# ATmega1284RFR2 device description
Architecture: AVR8; Family: megaAVR
Registers are 8-bit, access not given, no defined reset value unless marked. A register's access mark holds for its fields unless they carry their own. Offsets are from the block's base; [hi:lo] are bit positions; 'fields as' and 'values as' point back to an identical list.

## TC2 (TC8_ASYNC module) — Timer/Counter, 8-bit Async
Instances: TC2 0x00
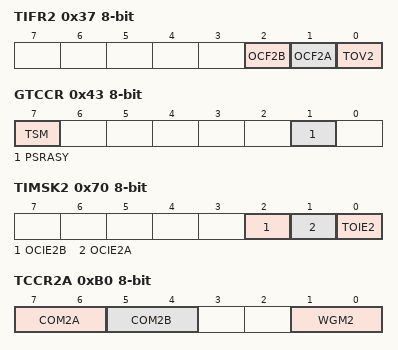
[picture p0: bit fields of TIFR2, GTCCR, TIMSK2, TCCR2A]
0x37 TIFR2 — Timer/Counter Interrupt Flag Register
  [2] OCF2B — Output Compare Flag 2 B
  [1] OCF2A — Output Compare Flag 2 A
  [0] TOV2 — Timer/Counter2 Overflow Flag
0x43 GTCCR — General Timer Counter Control register
  [7] TSM — Timer/Counter Synchronization Mode
  [1] PSRASY — Prescaler Reset Timer/Counter2
0x70 TIMSK2 — Timer/Counter Interrupt Mask register
  [2] OCIE2B — Timer/Counter2 Output Compare Match B Interrupt Enable
  [1] OCIE2A — Timer/Counter2 Output Compare Match A Interrupt Enable
  [0] TOIE2 — Timer/Counter2 Overflow Interrupt Enable
0xB0 TCCR2A — Timer/Counter2 Control Register A
  [7:6] COM2A — Compare Match Output A Mode
    0=Normal port operation, OC2A disconnected; 1=Toggle OC2A on Compare Match; 2=Clear OC2A on Compare Match; 3=Set OC2A on Compare Match
  [5:4] COM2B — Compare Match Output B Mode
    0=Normal port operation, OC2B disconnected; 1=Toggle OC2B on Compare Match; 2=Clear OC2B on Compare Match; 3=Set OC2B on Compare Match
  [1:0] WGM2 — Waveform Generation Mode
    0=Normal mode of operation; 1=PWM, phase correct, TOP=0xFF; 2=CTC, TOP = OCRA; 3=Fast PWM, TOP=0xFF; 5=PWM, Phase correct, TOP = OCRA; 7=Fast PWM, TOP=OCRA
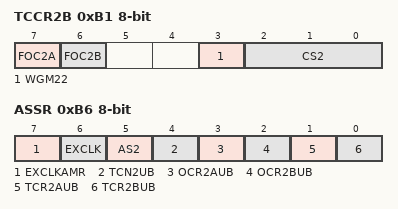
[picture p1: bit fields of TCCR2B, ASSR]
0xB1 TCCR2B — Timer/Counter2 Control Register B
  [7] FOC2A — Force Output Compare A
  [6] FOC2B — Force Output Compare B
  [3] WGM22 — Waveform Generation Mode
  [2:0] CS2 — Clock Select
    0=No clock source (Timer/Counter2 stopped); 1=clk_T2S/1 (no prescaling); 2=clk_T2S/8 (from prescaler); 3=clk_T2S/32 (from prescaler); 4=clk_T2S/64 (from prescaler); 5=clk_T2S/128 (from prescaler); 6=clk_T2S/256 (from prescaler); 7=clk_T2S/1024 (from prescaler)
0xB2 TCNT2 — Timer/Counter2
0xB3 OCR2A — Timer/Counter2 Output Compare Register A
0xB4 OCR2B — Timer/Counter2 Output Compare Register B
0xB6 ASSR — Asynchronous Status Register
  [7] EXCLKAMR — Enable External Clock Input for AMR
  [6] EXCLK — Enable External Clock Input
  [5] AS2 — Timer/Counter2 Asynchronous Mode
  [4] TCN2UB — Timer/Counter2 Update Busy
  [3] OCR2AUB — Timer/Counter2 Output Compare Register A Update Busy
  [2] OCR2BUB — Timer/Counter2 Output Compare Register B Update Busy
  [1] TCR2AUB — Timer/Counter2 Control Register A Update Busy
  [0] TCR2BUB — Timer/Counter2 Control Register B Update Busy

## WDT — Watchdog Timer
Instances: WDT 0x00
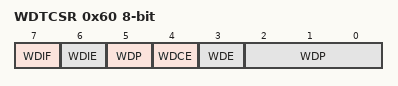
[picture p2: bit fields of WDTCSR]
0x60 WDTCSR — Watchdog Timer Control Register
  [7] WDIF — Watchdog Timeout Interrupt Flag
  [6] WDIE — Watchdog Timeout Interrupt Enable
  [4] WDCE — Watchdog Change Enable
  [3] WDE — Watch Dog Enable
  [5,2:0] WDP — Watchdog Timer Prescaler Bits
    0=Oscillator Cycles 2K; 1=Oscillator Cycles 4K; 2=Oscillator Cycles 8K; 3=Oscillator Cycles 16K; 4=Oscillator Cycles 32K; 5=Oscillator Cycles 64K; 6=Oscillator Cycles 128K; 7=Oscillator Cycles 256K; 8=Oscillator Cycles 512K; 9=Oscillator Cycles 1024K

## TC5 (TC16 module) — Timer/Counter, 16-bit
Instances: TC5 0x00
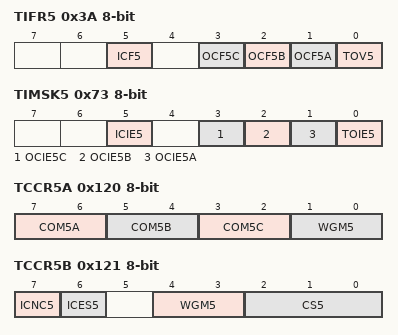
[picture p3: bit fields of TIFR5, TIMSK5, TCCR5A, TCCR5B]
0x3A TIFR5 — Timer/Counter5 Interrupt Flag Register
  [5] ICF5 — Timer/Counter5 Input Capture Flag
  [3] OCF5C — Timer/Counter5 Output Compare C Match Flag
  [2] OCF5B — Timer/Counter5 Output Compare B Match Flag
  [1] OCF5A — Timer/Counter5 Output Compare A Match Flag
  [0] TOV5 — Timer/Counter5 Overflow Flag
0x73 TIMSK5 — Timer/Counter5 Interrupt Mask Register
  [5] ICIE5 — Timer/Counter5 Input Capture Interrupt Enable
  [3] OCIE5C — Timer/Counter5 Output Compare C Match Interrupt Enable
  [2] OCIE5B — Timer/Counter5 Output Compare B Match Interrupt Enable
  [1] OCIE5A — Timer/Counter5 Output Compare A Match Interrupt Enable
  [0] TOIE5 — Timer/Counter5 Overflow Interrupt Enable
0x120 TCCR5A — Timer/Counter5 Control Register A
  [7:6] COM5A — Compare Output Mode for Channel A
    0=Normal operation
  [5:4] COM5B — Compare Output Mode for Channel B
    0=Normal operation
  [3:2] COM5C — Compare Output Mode for Channel C
    0=Normal operation
  [1:0] WGM5 — Waveform Generation Mode
    0=Normal mode of operation; 1=PWM, phase correct, 8-bit; 2=PWM, phase correct, 9-bit; 3=PWM, phase correct, 10-bit; 4=CTC, TOP = OCRnA; 5=Fast PWM, 8-bit; 6=Fast PWM, 9-bit; 7=Fast PWM, 10-bit; 8=PWM, Phase and frequency correct, TOP = ICRn; 9=PWM, Phase and frequency correct, TOP = OCRnA; 10=PWM, Phase correct, TOP = ICRn; 11=PWM, Phase correct, TOP = OCRnA; 12=CTC, TOP = OCRnA; 14=Fast PWM, TOP = ICRn; 15=Fast PWM, TOP = OCRnA
0x121 TCCR5B — Timer/Counter5 Control Register B
  [7] ICNC5 — Input Capture 5 Noise Canceller
  [6] ICES5 — Input Capture 5 Edge Select
  [4:3] WGM5 (bit 2 of the value upward) — Waveform Generation Mode
    values as TCCR5A.WGM5
  [2:0] CS5 — Clock Select
    0=No clock source (Timer/Counter stopped); 1=clk_IO/1 (no prescaling); 2=clk_IO/8 (from prescaler); 3=clk_IO/64 (from prescaler); 4=clk_IO/256 (from prescaler); 5=clk_IO/1024 (from prescaler)
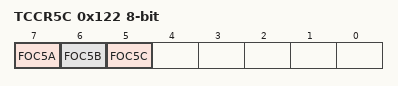
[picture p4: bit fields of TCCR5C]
0x122 TCCR5C — Timer/Counter5 Control Register C
  [7] FOC5A — Force Output Compare for Channel A
  [6] FOC5B — Force Output Compare for Channel B
  [5] FOC5C — Force Output Compare for Channel C
0x124 TCNT5 16-bit — Timer/Counter5 Bytes
0x126 ICR5 16-bit — Timer/Counter5 Input Capture Register Bytes
0x128 OCR5A 16-bit — Timer/Counter5 Output Compare Register A Bytes
0x12A OCR5B 16-bit — Timer/Counter5 Output Compare Register B Bytes
0x12C OCR5C 16-bit — Timer/Counter5 Output Compare Register C Bytes
